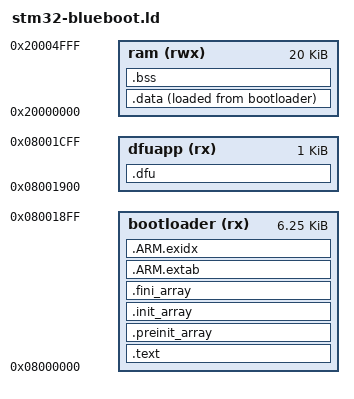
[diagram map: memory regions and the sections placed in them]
/*
 * This file is part of the libopencm3 project.
 *
 * Copyright (C) 2009 Uwe Hermann <uwe@hermann-uwe.de>
 *
 * This library is free software: you can redistribute it and/or modify
 * it under the terms of the GNU Lesser General Public License as published by
 * the Free Software Foundation, either version 3 of the License, or
 * (at your option) any later version.
 *
 * This library is distributed in the hope that it will be useful,
 * but WITHOUT ANY WARRANTY; without even the implied warranty of
 * MERCHANTABILITY or FITNESS FOR A PARTICULAR PURPOSE.  See the
 * GNU Lesser General Public License for more details.
 *
 * You should have received a copy of the GNU Lesser General Public License
 * along with this library.  If not, see <http://www.gnu.org/licenses/>.
 */

/* Linker script for Olimex STM32-H103 (STM32F103RBT6, 128K flash, 20K RAM). */

/* Define memory regions. */
MEMORY
{
	bootloader (rx): ORIGIN = 0x08000000, LENGTH = 6400
	dfuapp    (rx) : ORIGIN = 0x08001900, LENGTH = 1K
	ram (rwx) : ORIGIN = 0x20000000, LENGTH = 20K
}

/* Include the common ld script. */

/* IDEA: DEFINE OUR SECTIONS HERE AND HAVE SEPARATE SHIT FOR MAIN1 AND 2 TO JUMP INTO*/
/* INCLUDE cortex-m-generic.ld */

/* Enforce emmition of the vector table. */
EXTERN (vector_table)

/* Enforce emmittion of our own reset function, without this it will be optimized away since
*  there's no call to it */
EXTERN (reset_to_dfu)

/* Define the entry point of the output file. */
ENTRY(reset_handler)

/* Define sections. */
SECTIONS
{
	.text : {
		_vector_table_start = .;
		*(.vectors)		/*Vector table */
		*(.text*)	/* Program code */
		. = ALIGN(4);
		*(.rodata*)	/* Read-only data */
		. = ALIGN(4);
	} >bootloader

	.dfu : {
		_dfuapp_start = .;
		*(.reset_to_dfu)
		*(.dfu*)		/* Program code */
		. = ALIGN(4);
		*(.rodata*)		/* Read-only data */
		. = ALIGN(4);
	} >dfuapp

	/* C++ Static constructors/destructors, also used for __attribute__
	 * ((constructor)) and the likes */
	.preinit_array : {
		. = ALIGN(4);
		__preinit_array_start = .;
		KEEP (*(.preinit_array))
		__preinit_array_end = .;
	} >bootloader
	.init_array : {
		. = ALIGN(4);
		__init_array_start = .;
		KEEP (*(SORT(.init_array.*)))
		KEEP (*(.init_array))
		__init_array_end = .;
	} >bootloader
	.fini_array : {
		. = ALIGN(4);
		__fini_array_start = .;
		KEEP (*(.fini_array))
		KEEP (*(SORT(.fini_array.*)))
		__fini_array_end = .;
	} >bootloader

	/*
	 * Another section used by C++ stuff, appears when using newlib with
	 * 64bit (long long) printf support
	 */
	.ARM.extab : {
		*(.ARM.extab*)
	} >bootloader
	.ARM.exidx : {
		__exidx_start = .;
		*(.ARM.exidx*)
		__exidx_end = .;
	} >bootloader

	. = ALIGN(4);
	_etext = .;

	.data : {
		_data = .;
		*(.data*)	/* Read-write initialized data */
		. = ALIGN(4);
		_edata = .;
	} >ram AT >bootloader
	_data_loadaddr = LOADADDR(.data);

	.bss : {
		*(.bss*)	/* Read-write zero initialized data */
		*(COMMON)
		. = ALIGN(4);
		_ebss = .;
	} >ram

	/*
	 * The .eh_frame section appears to be used for C++ exception handling.
	 * You may need to fix this if you're using C++.
	 */
	/DISCARD/ : { *(.eh_frame) }

	. = ALIGN(4);
	end = .;
}

PROVIDE(_stack = ORIGIN(ram) + LENGTH(ram));

